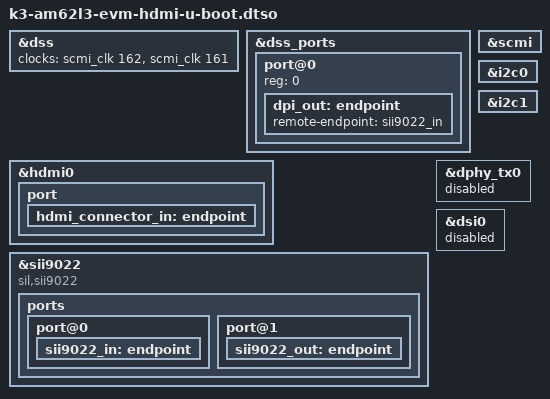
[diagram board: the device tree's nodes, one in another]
// SPDX-License-Identifier: GPL-2.0
/*
 * HDMI overlay for AM62L3 EVM U-Boot
 * Copyright (C) 2025 Texas Instruments Incorporated - https://www.ti.com/
 */

&dss {
	bootph-all;
	status = "okay";
	clocks = <&scmi_clk 162>,
			 <&scmi_clk 161>;
};

&dss_ports {
	bootph-all;
	/* VP1: DPI Output to HDMI Bridge */
	port@0 {
		reg = <0>;
		bootph-all;

		dpi_out: endpoint {
			remote-endpoint = <&sii9022_in>;
			bootph-all;
		};
	};
};

/* HDMI Connector - Reference to main device tree */
&hdmi0 {
	bootph-all;
	status = "okay";

	port {
		bootph-all;

		hdmi_connector_in: endpoint {
			bootph-all;
		};
	};
};

&scmi {
	bootph-all;
};

/* I2C Configuration for HDMI Bridge */
&i2c0 {
	bootph-all;
	status = "okay";
};

&i2c1 {
	bootph-all;
	status = "okay";
};

/* SII9022 HDMI Bridge - Reference to main device tree */
&sii9022 {
	bootph-all;
	compatible = "sil,sii9022";
	status = "okay";

	ports {
		bootph-all;

		port@0 {
			bootph-all;

			sii9022_in: endpoint {
				bootph-all;
			};
		};

		port@1 {
			bootph-all;

			sii9022_out: endpoint {
				bootph-all;
			};
		};
	};
};

&dphy_tx0 {
	status = "disabled";
};

&dsi0 {
	status = "disabled";
};
